AUTOSAR XML (schema 4-0-3)
standard types defined: boolean, float32, float64, sint16, sint32, sint8, uint16, uint32, uint8
package /ApplDataTypes
  app type ADT_TimeCount: category=VALUE
package /BSWScheduler/BswImplementations
  bsw implementation bswImplementation0: programming-language=C, sw-version=1.0.0, vendor-id=20, ar-release-version=1.0.0, behavior=BswImplementation_0, vendor-api-infix=abc
    code-descriptors:
      code Code: artifact-descriptors=autosar-engineering-object={short-label=Label, category=Category}
    resource consumption resourceConsumption
  bsw implementation bswImplementation1: programming-language=C, sw-version=1.0.0, vendor-id=20, ar-release-version=1.0.0, behavior=Can/InternalBehavior_0, vendor-api-infix=abc
    code-descriptors:
      code Code: artifact-descriptors=autosar-engineering-object={short-label=Label, category=Category}
    resource consumption resourceConsumption
  bsw implementation bswImplementation2: programming-language=C, sw-version=1.0.0, vendor-id=20, ar-release-version=1.0.0, behavior=CanIf/InternalBehavior_0, vendor-api-infix=abc
    code-descriptors:
      code Code: artifact-descriptors=autosar-engineering-object={short-label=Label, category=Category}
    resource consumption resourceConsumption
package /BSWScheduler/BswModuleDescriptions
  bsw module description Can: module-id=80, provided-entrys=Can_Init
    bsw internal behavior InternalBehavior_0
      exclusive area Reentrant
      bsw called entity Can_Init: can-enter-exclusive-area=Reentrant, implemented-entry=Can_Init
  bsw module description CanIf: module-id=60, provided-entrys=CanIf_Init
    bsw internal behavior InternalBehavior_0
      exclusive area Reentrant_0
      exclusive area Reentrant_1
      5 x bsw called entity:
        CanIf_Init: can-enter-exclusive-area=InternalBehavior_0/Reentrant_0, implemented-entry=CanIf_Init
        CanIf_TxConfirmation: can-enter-exclusive-area=InternalBehavior_0/Reentrant_1, implemented-entry=CanIf_TxConfirmation
        CanIf_RxIndication: can-enter-exclusive-area=InternalBehavior_0/Reentrant_0, implemented-entry=CanIf_RxIndication
        CanIf_ControllerBusOff: can-enter-exclusive-area=InternalBehavior_0/Reentrant_1, implemented-entry=CanIf_ControllerBusOff
        CanIf_ControllerModeIndication: can-enter-exclusive-area=InternalBehavior_0/Reentrant_1, implemented-entry=CanIf_ControllerModeIndication
  bsw module description Com: module-id=50, provided-entrys=[MainFunctionRx, MainFunctionTx]
    bsw internal behavior BswImplementation_0
      exclusive area Reentrant_{0..2}
      bsw schedulable entity MainFunctionRx: can-enter-exclusive-area=BswImplementation_0/Reentrant_0, implemented-entry=MainFunctionRx
      bsw schedulable entity MainFunctionTx: can-enter-exclusive-area=BswImplementation_0/Reentrant_0, implemented-entry=MainFunctionTx
      bsw called entity Com_TxConfirmation: can-enter-exclusive-area=BswImplementation_0/Reentrant_1, implemented-entry=Com_TxConfirmation
      bsw called entity Com_RxIndication: can-enter-exclusive-area=BswImplementation_0/Reentrant_0, implemented-entry=Com_RxIndication
      bsw called entity Com_InvalidateSignal: can-enter-exclusive-area=Reentrant_2, implemented-entry=Com_InvalidateSignal
      bsw timing event TimingEvent_MainFunctionRx: starts-on-event=MainFunctionRx, period=0.1
      bsw timing event TimingEvent_MainFunctionTx: starts-on-event=MainFunctionTx, period=0.1
package /BSWScheduler/BswModuleEntrys
  11 x bsw module entry, all with is-synchronous=true, sw-service-impl-policy=STANDARD:
    CanIf_ControllerBusOff: service-id=22, is-reentrant=true, call-type=CALLBACK, execution-context=UNSPECIFIED
    CanIf_ControllerModeIndication: service-id=23, is-reentrant=true, call-type=CALLBACK, execution-context=UNSPECIFIED
    CanIf_Init: service-id=1, is-reentrant=false, call-type=REGULAR, execution-context=TASK
    CanIf_RxIndication: service-id=20, is-reentrant=true, call-type=CALLBACK, execution-context=UNSPECIFIED
    CanIf_TxConfirmation: service-id=19, is-reentrant=true, call-type=CALLBACK, execution-context=UNSPECIFIED
    Can_Init: service-id=0, is-reentrant=false, call-type=REGULAR, execution-context=UNSPECIFIED
    Com_InvalidateSignal: service-id=16, is-reentrant=true, call-type=REGULAR, execution-context=TASK
    Com_RxIndication: service-id=66, is-reentrant=true, call-type=CALLBACK, execution-context=UNSPECIFIED
    Com_TxConfirmation: service-id=64, is-reentrant=true, call-type=CALLBACK, execution-context=UNSPECIFIED
    MainFunctionRx: service-id=24, is-reentrant=false, call-type=SCHEDULED, execution-context=TASK
    MainFunctionTx: service-id=25, is-reentrant=false, call-type=SCHEDULED, execution-context=TASK
package /HelloAutosar
  data type mapping set HA_DTM: data-type-map{application-data-type=ADT_TimeCount, implementation-data-type=IDT_TimeCount}
  composition sw component type HA_TopLevel
    component SWC2: type=SWC2
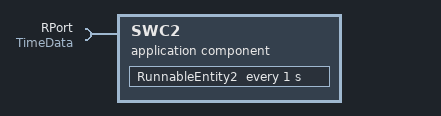
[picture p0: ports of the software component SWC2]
  application sw component type SWC2
    require port RPort: nonqueued-receiver-com-spec{data-element=time, enable-update=true, init-value=Value:0}, required-interface=TimeData
    behavior IB_SWC2: data-type-mapping=HA_DTM, handle-termination-and-restart=NO-SUPPORT
      timing event TimingEvent: start-on-event=RunnableEntity2, period=1
      runnable RunnableEntity2
        data-receive-point-by-arguments:
          access VariableAccess: accessed-variable=RPort.time
package /ImplDataTypes
  impl type IDT_TimeCount: category=VALUE, base-type=uint32
package /Interfaces
  sender receiver interface TimeData
    data time: type=ADT_TimeCount
package /Network
  pdu ISignalIPdu1: unused-bit-pattern=0
    signal ISignal1: 32 bit, data-type-policy=PORT-INTERFACE-DEFINITION
package /System
  ecuc value collection EcucValueCollection: ecu-extract=SystemHA, ecuc-values=[Os, Rte, Com, EcuC]
  system SystemHA: system-version=1.0.0
    system mapping SystemMapping: sender-receiver-to-signal-mapping{data-element=SWC2.RootSwCompositionPrototype.RPort.time, system-signal=SystemSignal1}
    root-software-compositions:
      root sw composition prototype RootSwCompositionPrototype: software-composition=HA_TopLevel
